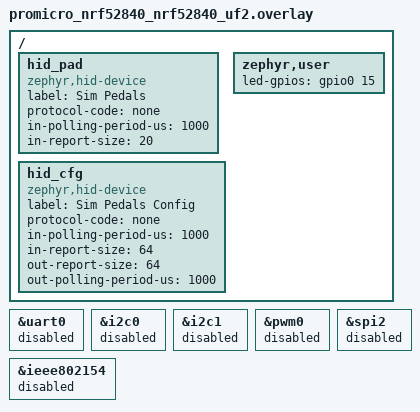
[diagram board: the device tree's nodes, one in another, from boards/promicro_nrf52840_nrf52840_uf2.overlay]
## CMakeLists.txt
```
cmake_minimum_required(VERSION 3.20.0)
find_package(Zephyr REQUIRED HINTS $ENV{ZEPHYR_BASE})
project(sim_hub)

target_include_directories(app PRIVATE ${CMAKE_CURRENT_SOURCE_DIR}/../common src)
target_sources(app PRIVATE
	src/main.c src/radio.c src/usb.c src/store.c src/usb_init.c
	../common/axis_proc.c)
```

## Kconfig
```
menu "Sim hub"

# Names kept identical to Zephyr's USB samples so usb_init.c (derived from the sample) works as is.
config SAMPLE_USBD_MANUFACTURER
	string "USB manufacturer string"
	default "DIY"

config SAMPLE_USBD_PRODUCT
	string "USB product string"
	default "Sim Pedals Hub"

config SAMPLE_USBD_PID
	hex "USB product ID"
	default 0x5E00

config SAMPLE_USBD_SELF_POWERED
	bool "Self powered attribute"

config SAMPLE_USBD_REMOTE_WAKEUP
	bool "Remote wakeup attribute"

config SAMPLE_USBD_MAX_POWER
	int "bMaxPower (2 mA units)"
	default 100

config SAMPLE_USBD_20_EXTENSION_DESC
	bool "USB 2.0 extension descriptor"

config HUB_IDLE_MINUTES
	int "Default pedal idle power-off time pushed to pedals (minutes)"
	default 20

config HUB_ACK_PAYLOAD
	bool "Send commands to pedals in ACK payloads"
	default y

config HUB_DIAG_LEVEL
	int "Bring-up ladder: 0 blinky only, 1 +USB, 2 +flash settings, 3 full hub"
	default 3

endmenu

source "Kconfig.zephyr"
```

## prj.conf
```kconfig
CONFIG_ESB=y
CONFIG_CLOCK_CONTROL=y
CONFIG_GPIO=y
CONFIG_HWINFO=y
CONFIG_REBOOT=y

# USB (new device stack), two HID interfaces: joystick + vendor config
CONFIG_USB_DEVICE_STACK_NEXT=y
CONFIG_USBD_HID_SUPPORT=y
CONFIG_USBD_CDC_ACM_CLASS=n
CONFIG_USB_DEVICE_STACK=n

# settings in flash (storage_partition, 32 kB)
CONFIG_FLASH=y
CONFIG_FLASH_MAP=y
CONFIG_FLASH_PAGE_LAYOUT=y
CONFIG_NVS=y
CONFIG_SETTINGS=y
CONFIG_SETTINGS_NVS=y

CONFIG_SERIAL=n
CONFIG_CONSOLE=n
CONFIG_UART_CONSOLE=n
CONFIG_LOG=n
CONFIG_PRINTK=n

CONFIG_ESB_MAX_PAYLOAD_LENGTH=32
CONFIG_ESB_TX_FIFO_SIZE=8
CONFIG_ESB_RX_FIFO_SIZE=8
CONFIG_ESB_PIPE_COUNT=8
CONFIG_MAIN_STACK_SIZE=4096
CONFIG_SYSTEM_WORKQUEUE_STACK_SIZE=2048
CONFIG_BUILD_OUTPUT_UF2=y

# 32 kHz source: RC is safe on clones without the 32.768 kHz crystal
CONFIG_CLOCK_CONTROL_NRF_K32SRC_RC=y
CONFIG_CLOCK_CONTROL_NRF_K32SRC_500PPM=y
```

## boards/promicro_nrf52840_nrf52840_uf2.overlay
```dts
#include <zephyr/dt-bindings/gpio/gpio.h>
/* Hub: USB gamepad (8 axes, 32 buttons) + vendor config interface */
&uart0 { status = "disabled"; };
&i2c0  { status = "disabled"; };
&i2c1  { status = "disabled"; };
&pwm0  { status = "disabled"; };
&spi2  { status = "disabled"; };
&ieee802154 { status = "disabled"; };

/ {
	hid_pad: hid_pad {
		compatible = "zephyr,hid-device";
		label = "Sim Pedals";
		protocol-code = "none";
		in-polling-period-us = <1000>;
		in-report-size = <20>;
	};

	hid_cfg: hid_cfg {
		compatible = "zephyr,hid-device";
		label = "Sim Pedals Config";
		protocol-code = "none";
		in-polling-period-us = <1000>;
		in-report-size = <64>;
		out-report-size = <64>;
		out-polling-period-us = <1000>;
	};

	zephyr,user {
		led-gpios = <&gpio0 15 GPIO_ACTIVE_HIGH>;
	};
};
```

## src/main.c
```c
#include <zephyr/kernel.h>
#include <zephyr/drivers/gpio.h>
#include <zephyr/fatal.h>
#include <zephyr/sys/reboot.h>
#include "hub.h"

/* ---- crash diagnostics (no serial available): last stage + fault reason survive a soft reset ---- */
struct dbg { uint32_t magic, stage, reason, pc; };
static __noinit struct dbg dbg;
#define DBG_MAGIC 0xD3B6C0DEu
#define STAGE(n) (dbg.stage = (n))

void k_sys_fatal_error_handler(unsigned int reason, const struct arch_esf *esf)
{
	dbg.magic = DBG_MAGIC;
	dbg.reason = reason + 1;
	dbg.pc = esf ? esf->basic.pc : 0;
	sys_reboot(SYS_REBOOT_COLD);
}

struct dev_state g_dev[N_TYPES];
bool g_dirty;
struct k_spinlock g_lock;
struct hub_stats g_stats;

static const struct gpio_dt_spec led = GPIO_DT_SPEC_GET(DT_PATH(zephyr_user), led_gpios);

/* Give every axis of a freshly seen device the next free HID axis (needs g_lock). */
void assign_slots_locked(uint8_t t)
{
	struct dev_state *d = &g_dev[t];

	for (int a = 0; a < d->n_axes && a < PP_MAX_AXES_PER_DEV; a++) {
		if (g_cfg[t][a].slot != PP_SLOT_AUTO) {
			continue;
		}
		uint8_t used = 0;

		for (int tt = 1; tt < N_TYPES; tt++) {
			for (int aa = 0; aa < PP_MAX_AXES_PER_DEV; aa++) {
				if (g_cfg[tt][aa].slot < PP_HID_AXES) {
					used |= BIT(g_cfg[tt][aa].slot);
				}
			}
		}
		for (int s = 0; s < PP_HID_AXES; s++) {
			if (!(used & BIT(s))) {
				g_cfg[t][a].slot = s;
				g_dirty = true;
				break;
			}
		}
		if (g_cfg[t][a].slot == PP_SLOT_AUTO) {
			g_cfg[t][a].slot = PP_SLOT_OFF;        /* out of HID axes */
		}
	}
}

void hub_outputs(uint16_t axes[PP_HID_AXES], int64_t now)
{
	k_spinlock_key_t k = k_spin_lock(&g_lock);

	for (int i = 0; i < PP_HID_AXES; i++) {
		axes[i] = 0;
	}
	for (int t = 1; t < N_TYPES; t++) {
		struct dev_state *d = &g_dev[t];
		bool ok = d->seen && (now - d->last_rx_ms) < LINK_TIMEOUT_MS;

		if (now - d->pps_t0 >= 1000) {          /* packets per second, also falls to 0 */
			d->pps = d->pkt_cnt;
			d->pkt_cnt = 0;
			d->pps_t0 = now;
		}

		if (!ok && d->alive) {
			d->alive = false;                   /* link lost -> re-push settings on return */
		}
		for (int a = 0; a < d->n_axes; a++) {
			uint8_t s = g_cfg[t][a].slot;

			if (s < PP_HID_AXES) {
				axes[s] = ok ? d->out[a] : 0;     /* failsafe: zero */
			}
		}
	}
	k_spin_unlock(&g_lock, k);
}

static void blinks(int n, int on_ms, int off_ms)
{
	for (int i = 0; i < n; i++) {
		gpio_pin_set_dt(&led, 1);
		k_msleep(on_ms);
		gpio_pin_set_dt(&led, 0);
		k_msleep(off_ms);
	}
}

static void blink_code(int n)
{
	/* n quick blinks, long pause, forever (USB keeps running in its own threads) */
	for (;;) {
		blinks(n, 150, 250);
		k_msleep(1500);
	}
}

/* After a crash: stage blinks (slow), pause, reason blinks (fast), 3 times, then try again. */
static void show_crash(void)
{
	int rc = dbg.reason < 6 ? (int)dbg.reason : 6 + MIN((int)dbg.reason - 17, 3);

	for (int r = 0; r < 3; r++) {
		blinks(dbg.stage, 500, 500);
		k_msleep(1500);
		blinks(rc, 120, 200);
		k_msleep(3000);
	}
	dbg.reason = 0;
}

static void diag_loop(int level)
{
	/* distinguishable patterns for the bring-up ladder */
	for (;;) {
		switch (level) {
		case 0: blinks(1, 500, 500); break;                       /* 1 Hz symmetric */
		case 1: blinks(1, 60, 1940); break;                       /* one blip per 2 s */
		default: blinks(2, 60, 200); k_msleep(1500); break;       /* double blip per 2 s */
		}
	}
}

int main(void)
{
	gpio_pin_configure_dt(&led, GPIO_OUTPUT_ACTIVE);   /* solid LED = app is running */
	if (dbg.magic != DBG_MAGIC) {
		dbg.magic = DBG_MAGIC;
		dbg.stage = 0;
		dbg.reason = 0;
	} else if (dbg.reason) {
		show_crash();
	}
	STAGE(1);
	defaults_all();
	if (CONFIG_HUB_DIAG_LEVEL == 0) {
		diag_loop(0);
	}

	/* USB first, so the PC sees the device even if flash/radio init has problems */
	STAGE(2);
	int err = usb_start();
	if (err) {
		blink_code(1);
	}
	STAGE(3);
	if (CONFIG_HUB_DIAG_LEVEL == 1) {
		diag_loop(1);
	}
	k_msleep(300);
	STAGE(4);
	store_load();                   /* settings from flash (defaults if empty) */
	if (CONFIG_HUB_DIAG_LEVEL == 2) {
		diag_loop(2);
	}

	STAGE(5);
	err = radio_start();
	if (err) {
		blink_code(2);
	}
	STAGE(6);
	for (;;) {                      /* slow heartbeat + live stream to the PC app (100 Hz) */
		for (int i = 0; i < 100; i++) {
			usb_cfg_enqueue_live();
			k_msleep(10);
		}
		gpio_pin_toggle_dt(&led);
	}
	return 0;
}
```

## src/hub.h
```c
#ifndef HUB_H
#define HUB_H
#include <zephyr/kernel.h>
#include "pedal_protocol.h"
#include "axis_proc.h"

#define FW_MAJOR 1
#define FW_MINOR 0
#define N_TYPES  (PP_DEV_MAX_TYPE + 1)   /* index = dev_type (0 unused) */
#define LINK_TIMEOUT_MS 50               /* after this the device's axes fall to 0 */

struct dev_state {
	bool     seen;
	bool     alive;
	int64_t  last_rx_ms;
	uint32_t uid;
	uint8_t  batt_20mv, flags, n_axes;
	struct pp_diag diag;
	int32_t  raw[PP_MAX_AXES_PER_DEV];
	int32_t  filt[PP_MAX_AXES_PER_DEV];
	uint16_t out[PP_MAX_AXES_PER_DEV];
	struct axis_state st[PP_MAX_AXES_PER_DEV];
	uint16_t pps, pkt_cnt;
	int64_t  pps_t0;
	uint8_t  pend_cmd, pend_p0;      /* next ACK payload */
};

extern struct dev_state g_dev[N_TYPES];
extern struct pp_axis_cfg g_cfg[N_TYPES][PP_MAX_AXES_PER_DEV];
struct hub_stats { uint32_t rx_ok, tx_ok; uint16_t rx_bad; uint8_t bad_len, bad_b0; };
extern struct hub_stats g_stats;
extern uint8_t g_idle_min;
extern bool g_dirty;                 /* config changed by auto slot assignment */
extern struct k_spinlock g_lock;

void defaults_all(void);
int  store_load(void);
int  store_save(void);

int  radio_start(void);

void assign_slots_locked(uint8_t t);          /* needs g_lock */
void hub_outputs(uint16_t axes[PP_HID_AXES], int64_t now);

int  usb_start(void);
void usb_cfg_enqueue_live(void);
#endif
```

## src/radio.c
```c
#include "hub.h"
#if IS_ENABLED(CONFIG_ESB)
#include <zephyr/drivers/clock_control/nrf_clock_control.h>
#include <esb.h>
#include <string.h>

static uint8_t ack_queued[N_TYPES];
static uint16_t rx_since_ack[N_TYPES];

static void queue_ack(uint8_t t)
{
	struct esb_payload ack = {.pipe = t, .length = sizeof(struct pp_ack)};
	struct pp_ack *a = (struct pp_ack *)ack.data;
	struct dev_state *d = &g_dev[t];

	a->type = PP_PKT_ACK;
	a->cmd = d->pend_cmd;
	a->p0 = d->pend_p0;
	a->p1 = 0;
	if (esb_write_payload(&ack) == 0) {
		ack_queued[t] = 1;
		rx_since_ack[t] = 0;
		d->pend_cmd = PP_CMD_NONE;
	}
}

static void on_data(const struct esb_payload *p)
{
	const struct pp_data *m = (const struct pp_data *)p->data;
	uint8_t t = p->pipe;

	/* p->data has a fixed buffer size; only p->length bytes are valid. */
	if (p->length < PP_DATA_HDR_LEN) {
		g_stats.rx_bad++;
		g_stats.bad_len = p->length;
		g_stats.bad_b0 = p->length ? p->data[0] : 0;
		return;
	}
	if (m->type != PP_PKT_DATA || t < 1 || t > PP_DEV_MAX_TYPE ||
	    m->dev_type != t || m->n_axes == 0 || m->n_axes > PP_MAX_AXES_PER_DEV) {
		g_stats.rx_bad++;
		g_stats.bad_len = p->length;
		g_stats.bad_b0 = p->data[0];
		return;
	}
	bool has_diag = (m->flags & PP_FLAG_DIAG_EXT) != 0;
	size_t expected_len = has_diag ? PP_DATA_DIAG_LEN(m->n_axes) : PP_DATA_LEN(m->n_axes);
	if (p->length != expected_len ||
	    (has_diag && (t != PP_DEV_PEDALS || m->n_axes != 3)) ||
	    (has_diag && !(m->flags & PP_FLAG_SENSOR_ERR))) {
		g_stats.rx_bad++;
		g_stats.bad_len = p->length;
		g_stats.bad_b0 = p->data[0];
		return;
	}
	int64_t now = k_uptime_get();
	k_spinlock_key_t k = k_spin_lock(&g_lock);
	struct dev_state *d = &g_dev[t];

	if (!d->alive) {                      /* device (re)appeared: push idle timeout to it */
		d->pend_cmd = PP_CMD_SET_IDLE;
		d->pend_p0 = g_idle_min;
	}
	d->alive = true;
	d->seen = true;
	d->last_rx_ms = now;
	d->uid = m->uid;
	d->flags = m->flags;
	d->batt_20mv = m->batt_20mv;
	d->n_axes = m->n_axes;
	if (has_diag) {
		memcpy(&d->diag, &m->axes[m->n_axes * 3], sizeof(d->diag));
	} else {
		memset(&d->diag, 0, sizeof(d->diag));
	}
	for (int i = 0; i < m->n_axes; i++) {
		int32_t raw = pp_get_i24(&m->axes[i * 3]);

		d->raw[i] = raw;
		d->out[i] = axis_process(&g_cfg[t][i], &d->st[i], raw, &d->filt[i]);
	}
	assign_slots_locked(t);
	d->pkt_cnt++;
	g_stats.rx_ok++;
	k_spin_unlock(&g_lock, k);

	if (ack_queued[t] && ++rx_since_ack[t] > 100) {   /* ACK never got out: reset FIFO */
		esb_flush_tx();
		memset(ack_queued, 0, sizeof(ack_queued));
	}
	if (IS_ENABLED(CONFIG_HUB_ACK_PAYLOAD) && !ack_queued[t]) {
		queue_ack(t);
	}
}

static void esb_handler(struct esb_evt const *ev)
{
	static struct esb_payload rx;

	switch (ev->evt_id) {
	case ESB_EVENT_TX_SUCCESS:             /* an ACK payload went out */
		g_stats.tx_ok++;
		for (int t = 1; t < N_TYPES; t++) {
			ack_queued[t] = 0;
		}
		break;
	case ESB_EVENT_RX_RECEIVED:
		while (esb_read_rx_payload(&rx) == 0) {
			on_data(&rx);
		}
		break;
	default:
		break;
	}
}

static int clocks_start(void)
{
	struct onoff_manager *mgr = z_nrf_clock_control_get_onoff(CLOCK_CONTROL_NRF_SUBSYS_HF);
	struct onoff_client cli;
	int res, err;

	if (!mgr) {
		return -ENXIO;
	}
	sys_notify_init_spinwait(&cli.notify);
	err = onoff_request(mgr, &cli);
	if (err < 0) {
		return err;
	}
	do {
		err = sys_notify_fetch_result(&cli.notify, &res);
	} while (err == -EAGAIN);
	return err ? err : res;
}

int radio_start(void)
{
	uint8_t b0[4] = PP_BASE_ADDR_0, b1[4] = PP_BASE_ADDR_1, pf[8] = PP_PREFIXES;
	struct esb_config c = ESB_DEFAULT_CONFIG;
	int err;

	if ((err = clocks_start())) {
		return err;
	}
	c.protocol = ESB_PROTOCOL_ESB_DPL;
	c.mode = ESB_MODE_PRX;
	c.event_handler = esb_handler;
	c.bitrate = ESB_BITRATE_2MBPS;
	c.crc = ESB_CRC_16BIT;
	c.selective_auto_ack = false;

	if ((err = esb_init(&c)) || (err = esb_set_base_address_0(b0)) ||
	    (err = esb_set_base_address_1(b1)) || (err = esb_set_prefixes(pf, 8)) ||
	    (err = esb_set_rf_channel(PP_RF_CHANNEL))) {
		return err;
	}
	return esb_start_rx();
}

#else
int radio_start(void) { return 0; }
#endif
```

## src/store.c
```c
#include <string.h>
#include <zephyr/settings/settings.h>
#include "hub.h"

#define STORE_MAGIC 0x50454431u   /* "PED1" */

struct blob {
	uint32_t magic;
	struct pp_axis_cfg cfg[PP_MAX_AXES_PER_DEV];
};

struct pp_axis_cfg g_cfg[N_TYPES][PP_MAX_AXES_PER_DEV];
uint8_t g_idle_min = CONFIG_HUB_IDLE_MINUTES;

void defaults_all(void)
{
	for (int t = 0; t < N_TYPES; t++) {
		for (int a = 0; a < PP_MAX_AXES_PER_DEV; a++) {
			axis_defaults(&g_cfg[t][a], 0, 1000000);
		}
	}
	/* pedals: Hall axes are 14-bit (centered around ~7500 at 3.3 V), brake is ADS1220 24-bit */
	axis_defaults(&g_cfg[PP_DEV_PEDALS][PP_PEDAL_CLUTCH], 4000, 12000);
	axis_defaults(&g_cfg[PP_DEV_PEDALS][PP_PEDAL_THROTTLE], 4000, 12000);
	axis_defaults(&g_cfg[PP_DEV_PEDALS][PP_PEDAL_BRAKE], 0, 1000000);
	g_cfg[PP_DEV_PEDALS][PP_PEDAL_BRAKE].full_scale_dkg = 1000;   /* 100 kg, set by calibration */
	for (int a = 3; a < PP_MAX_AXES_PER_DEV; a++) {
		g_cfg[PP_DEV_PEDALS][a].slot = PP_SLOT_OFF;
	}
	g_idle_min = CONFIG_HUB_IDLE_MINUTES;
}

static int set_cb(const char *name, size_t len, settings_read_cb read_cb, void *cb_arg)
{
	if (name[0] == 'd' && name[1] >= '1' && name[1] <= '7' && name[2] == 0) {
		struct blob b;
		int t = name[1] - '0';

		if (len == sizeof(b) && read_cb(cb_arg, &b, sizeof(b)) == sizeof(b) &&
		    b.magic == STORE_MAGIC) {
			for (int a = 0; a < PP_MAX_AXES_PER_DEV; a++) {
				axis_cfg_validate(&b.cfg[a]);
			}
			memcpy(g_cfg[t], b.cfg, sizeof(b.cfg));
		}
		return 0;
	}
	if (!strcmp(name, "idle")) {
		uint8_t v;

		if (read_cb(cb_arg, &v, 1) == 1) {
			g_idle_min = v;
		}
	}
	return 0;
}

SETTINGS_STATIC_HANDLER_DEFINE(hub, "hub", NULL, set_cb, NULL, NULL);

int store_load(void)
{
	defaults_all();
	int err = settings_subsys_init();

	if (err) {
		return err;
	}
	return settings_load_subtree("hub");
}

int store_save(void)
{
	struct blob b;
	char key[] = "hub/dX";
	int err = 0;

	for (int t = 1; t <= PP_DEV_MAX_TYPE; t++) {
		k_spinlock_key_t k = k_spin_lock(&g_lock);

		b.magic = STORE_MAGIC;
		memcpy(b.cfg, g_cfg[t], sizeof(b.cfg));
		k_spin_unlock(&g_lock, k);
		key[5] = (char)('0' + t);
		err |= settings_save_one(key, &b, sizeof(b));
	}
	err |= settings_save_one("hub/idle", &g_idle_min, 1);
	g_dirty = false;
	return err;
}
```

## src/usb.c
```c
/*
 * USB side of the hub:
 *   interface 0: HID joystick, 8 x 16-bit axes + 32 buttons (static descriptor, 20-byte report)
 *   interface 1: vendor HID (usage page 0xFF00), 64-byte in/out reports, config + live data
 */
#include <string.h>
#include <zephyr/device.h>
#include <zephyr/usb/usbd.h>
#include <zephyr/usb/class/usbd_hid.h>
#include <zephyr/sys/reboot.h>
#include <zephyr/drivers/hwinfo.h>
#include <nrf.h>
#include "hub.h"
#include "usb_init.h"

/* ------------------------------------------------------------- descriptors */
static const uint8_t pad_desc[] = {
	0x05, 0x01,             /* Usage Page (Generic Desktop) */
	0x09, 0x04,             /* Usage (Joystick) */
	0xA1, 0x01,             /* Collection (Application) */
	0x09, 0x30, 0x09, 0x31, 0x09, 0x32, 0x09, 0x33,   /* X Y Z Rx */
	0x09, 0x34, 0x09, 0x35, 0x09, 0x36, 0x09, 0x37,   /* Ry Rz Slider Dial */
	0x15, 0x00,             /* Logical Min 0 */
	0x27, 0xFF, 0xFF, 0x00, 0x00,   /* Logical Max 65535 */
	0x75, 0x10,             /* Report Size 16 */
	0x95, 0x08,             /* Report Count 8 */
	0x81, 0x02,             /* Input (Data,Var,Abs) */
	0x05, 0x09,             /* Usage Page (Button) */
	0x19, 0x01, 0x29, 0x20, /* Buttons 1..32 */
	0x15, 0x00, 0x25, 0x01,
	0x75, 0x01, 0x95, 0x20,
	0x81, 0x02,
	0xC0,
};
#define PAD_REPORT_LEN 20

static const uint8_t cfg_desc[] = {
	0x06, 0x00, 0xFF,       /* Usage Page (Vendor 0xFF00) */
	0x09, 0x01,             /* Usage (1) */
	0xA1, 0x01,             /* Collection (Application) */
	0x09, 0x02, 0x15, 0x00, 0x26, 0xFF, 0x00, 0x75, 0x08, 0x95, 0x40, 0x81, 0x02,  /* Input 64 */
	0x09, 0x03, 0x15, 0x00, 0x26, 0xFF, 0x00, 0x75, 0x08, 0x95, 0x40, 0x91, 0x02,  /* Output 64 */
	0xC0,
};

static const struct device *pad_dev = DEVICE_DT_GET(DT_NODELABEL(hid_pad));
static const struct device *cfg_dev = DEVICE_DT_GET(DT_NODELABEL(hid_cfg));

/* ------------------------------------------------------------- joystick */
static uint8_t pad_report[PAD_REPORT_LEN] __aligned(4);
static K_SEM_DEFINE(pad_done, 0, 1);
static volatile bool pad_ready;
static uint32_t g_buttons;

static void pad_iface_ready(const struct device *d, const bool ready)
{
	pad_ready = ready;
	if (ready) {
		k_sem_give(&pad_done);
	}
}
static void pad_in_done(const struct device *d, const uint8_t *r)
{
	k_sem_give(&pad_done);
}
static int pad_get_report(const struct device *d, const uint8_t t, const uint8_t id,
			  const uint16_t len, uint8_t *const buf)
{
	if (t != 1 /* input */ || len < PAD_REPORT_LEN) {
		return -ENOTSUP;
	}
	memcpy(buf, pad_report, PAD_REPORT_LEN);
	return PAD_REPORT_LEN;
}
static const struct hid_device_ops pad_ops = {
	.iface_ready = pad_iface_ready,
	.get_report = pad_get_report,
	.input_report_done = pad_in_done,
};

static void pad_thread(void *a, void *b, void *c)
{
	for (;;) {
		k_sem_take(&pad_done, K_MSEC(20));
		if (!pad_ready) {
			continue;
		}
		uint16_t ax[PP_HID_AXES];

		hub_outputs(ax, k_uptime_get());
		for (int i = 0; i < PP_HID_AXES; i++) {
			pad_report[2 * i] = ax[i] & 0xFF;
			pad_report[2 * i + 1] = ax[i] >> 8;
		}
		memcpy(&pad_report[16], &g_buttons, 4);
		if (hid_device_submit_report(pad_dev, PAD_REPORT_LEN, pad_report)) {
			k_msleep(1);
			k_sem_give(&pad_done);   /* retry */
		}
	}
}
K_THREAD_DEFINE(pad_tid, 2048, pad_thread, NULL, NULL, NULL, 5, 0, 0);

/* ------------------------------------------------------------- config channel */
struct frame { uint8_t d[PP_CFG_REPORT_LEN]; };
K_MSGQ_DEFINE(rx_q, sizeof(struct frame), 8, 4);
K_MSGQ_DEFINE(tx_q, sizeof(struct frame), 8, 4);
static K_SEM_DEFINE(cfg_tx_done, 1, 1);
static volatile bool cfg_ready, stream_on;
static uint8_t live_ctr;

static void cfg_iface_ready(const struct device *d, const bool ready)
{
	cfg_ready = ready;
	if (!ready) {
		stream_on = false;
	}
}
static void cfg_in_done(const struct device *d, const uint8_t *r)
{
	k_sem_give(&cfg_tx_done);
}
static void cfg_out(const struct device *d, const uint16_t len, const uint8_t *const buf)
{
	struct frame f = {0};

	memcpy(f.d, buf, MIN(len, PP_CFG_REPORT_LEN));
	k_msgq_put(&rx_q, &f, K_NO_WAIT);
}
static int cfg_set_report(const struct device *d, const uint8_t t, const uint8_t id,
			  const uint16_t len, const uint8_t *const buf)
{
	if (t == 2 /* output */) {
		cfg_out(d, len, buf);
		return 0;
	}
	return -ENOTSUP;
}
static int cfg_get_report(const struct device *d, const uint8_t t, const uint8_t id,
			  const uint16_t len, uint8_t *const buf)
{
	return -ENOTSUP;
}
static const struct hid_device_ops cfg_ops = {
	.iface_ready = cfg_iface_ready,
	.get_report = cfg_get_report,
	.set_report = cfg_set_report,
	.input_report_done = cfg_in_done,
	.output_report = cfg_out,
};

static void tx_thread(void *a, void *b, void *c)
{
	static struct frame f __aligned(4);

	for (;;) {
		k_msgq_get(&tx_q, &f, K_FOREVER);
		if (!cfg_ready) {
			continue;
		}
		if (k_sem_take(&cfg_tx_done, K_MSEC(100)) != 0) {
			k_sem_give(&cfg_tx_done);      /* host not reading: drop, don't wedge */
			continue;
		}
		if (hid_device_submit_report(cfg_dev, PP_CFG_REPORT_LEN, f.d)) {
			k_sem_give(&cfg_tx_done);
		}
	}
}
K_THREAD_DEFINE(tx_tid, 2048, tx_thread, NULL, NULL, NULL, 6, 0, 0);

static void reply(const uint8_t *req, uint8_t status, const void *data, size_t n)
{
	struct frame f = {0};

	f.d[0] = req[0];
	f.d[1] = req[1];
	f.d[2] = status;
	if (data && n) {
		memcpy(&f.d[3], data, MIN(n, PP_CFG_REPORT_LEN - 3));
	}
	k_msgq_put(&tx_q, &f, K_MSEC(20));
}

static void handle(const uint8_t *r)
{
	uint8_t cmd = r[0];
	uint8_t t = r[2], a = r[3];

	switch (cmd) {
	case PP_CMD_GET_INFO: {
		uint8_t info[16] = {PP_VERSION, FW_MAJOR, FW_MINOR, PP_HID_AXES, 0, g_idle_min};
		uint32_t id = NRF_FICR->DEVICEID[0];

		for (int i = 1; i < N_TYPES; i++) {
			if (g_dev[i].seen) {
				info[4] |= BIT(i);
			}
		}
		memcpy(&info[6], &id, 4);
		reply(r, PP_ST_OK, info, sizeof(info));
		break;
	}
	case PP_CMD_GET_AXIS: {
		if (t < 1 || t > PP_DEV_MAX_TYPE || a >= PP_MAX_AXES_PER_DEV) {
			reply(r, PP_ST_BADARG, NULL, 0);
			break;
		}
		struct pp_axis_cfg c;
		k_spinlock_key_t k = k_spin_lock(&g_lock);
		c = g_cfg[t][a];
		k_spin_unlock(&g_lock, k);
		reply(r, PP_ST_OK, &c, sizeof(c));
		break;
	}
	case PP_CMD_SET_AXIS: {
		struct pp_axis_cfg c;

		if (t < 1 || t > PP_DEV_MAX_TYPE || a >= PP_MAX_AXES_PER_DEV) {
			reply(r, PP_ST_BADARG, NULL, 0);
			break;
		}
		memcpy(&c, &r[4], sizeof(c));
		axis_cfg_validate(&c);
		k_spinlock_key_t k = k_spin_lock(&g_lock);
		g_cfg[t][a] = c;
		g_dev[t].st[a].primed = 0;
		assign_slots_locked(t);
		k_spin_unlock(&g_lock, k);
		reply(r, PP_ST_OK, NULL, 0);
		break;
	}
	case PP_CMD_SAVE:
		reply(r, store_save() ? PP_ST_UNKNOWN : PP_ST_OK, NULL, 0);
		break;
	case PP_CMD_DEFAULTS: {
		k_spinlock_key_t k = k_spin_lock(&g_lock);
		defaults_all();
		k_spin_unlock(&g_lock, k);
		reply(r, PP_ST_OK, NULL, 0);
		break;
	}
	case PP_CMD_TARE: {
		if (t < 1 || t > PP_DEV_MAX_TYPE || a >= PP_MAX_AXES_PER_DEV || !g_dev[t].alive) {
			reply(r, PP_ST_NODEV, NULL, 0);
			break;
		}
		k_spinlock_key_t k = k_spin_lock(&g_lock);
		g_cfg[t][a].cal_min = g_dev[t].filt[a];
		k_spin_unlock(&g_lock, k);
		reply(r, PP_ST_OK, NULL, 0);
		break;
	}
	case PP_CMD_STREAM:
		stream_on = r[2] != 0;
		reply(r, PP_ST_OK, NULL, 0);
		break;
	case PP_CMD_DEV_CMD: {         /* payload: dev_type, ack_cmd, p0 */
		if (t < 1 || t > PP_DEV_MAX_TYPE) {
			reply(r, PP_ST_BADARG, NULL, 0);
			break;
		}
		k_spinlock_key_t k = k_spin_lock(&g_lock);
		g_dev[t].pend_cmd = r[3];
		g_dev[t].pend_p0 = r[4];
		if (r[3] == PP_CMD_SET_IDLE) {
			g_idle_min = r[4];
		}
		k_spin_unlock(&g_lock, k);
		reply(r, PP_ST_OK, NULL, 0);
		break;
	}
	case PP_CMD_BOOTLOADER:
		reply(r, PP_ST_OK, NULL, 0);
		k_msleep(100);
		NRF_POWER->GPREGRET = 0x57;          /* Adafruit UF2 bootloader magic */
		sys_reboot(SYS_REBOOT_COLD);
		break;
	default:
		reply(r, PP_ST_UNKNOWN, NULL, 0);
		break;
	}
}

static void rx_thread(void *a, void *b, void *c)
{
	struct frame f;
	int64_t last_save = 0;

	for (;;) {
		if (k_msgq_get(&rx_q, &f, K_MSEC(500)) == 0) {
			handle(f.d);
		}
		/* slots were auto-assigned by a new device: persist after things settle */
		if (g_dirty && k_uptime_get() - last_save > 3000) {
			last_save = k_uptime_get();
			store_save();
		}
	}
}
K_THREAD_DEFINE(rx_tid, 4096, rx_thread, NULL, NULL, NULL, 7, 0, 0);

/* live frame: [0]=PP_CMD_LIVE [1]=ctr [2]=ndev, per device:
 *   type u8, batt_20mv u8, flags u8, alive u8, pps u16, n u8, n x { raw i32, out u16 } */
void usb_cfg_enqueue_live(void)
{
	if (!stream_on || !cfg_ready || k_msgq_num_used_get(&tx_q) > 0) {
		return;
	}
	struct frame f = {0};
	int pos = 3, nd = 0;
	int64_t now = k_uptime_get();
	k_spinlock_key_t k = k_spin_lock(&g_lock);

	for (int t = 1; t < N_TYPES; t++) {
		struct dev_state *d = &g_dev[t];

		if (!d->seen) {
			continue;
		}
		int n = d->n_axes;
		bool has_diag = (d->flags & PP_FLAG_DIAG_EXT) != 0;
		int extra = has_diag ? PP_DIAG_LEN : 0;

		if (pos + 7 + 6 * n + extra > 52) {
			break;
		}
		f.d[pos++] = t;
		f.d[pos++] = d->batt_20mv;
		f.d[pos++] = d->flags;
		f.d[pos++] = (now - d->last_rx_ms) < LINK_TIMEOUT_MS;
		f.d[pos++] = d->pps & 0xFF;
		f.d[pos++] = d->pps >> 8;
		f.d[pos++] = n;
		for (int i = 0; i < n; i++) {
			memcpy(&f.d[pos], &d->raw[i], 4);
			pos += 4;
			f.d[pos++] = d->out[i] & 0xFF;
			f.d[pos++] = d->out[i] >> 8;
		}
		if (has_diag) {
			memcpy(&f.d[pos], &d->diag, PP_DIAG_LEN);
			pos += PP_DIAG_LEN;
		}
		nd++;
	}
	memcpy(&f.d[52], &g_stats.rx_ok, 4);
	memcpy(&f.d[56], &g_stats.tx_ok, 4);
	memcpy(&f.d[60], &g_stats.rx_bad, 2);
	f.d[62] = g_stats.bad_len;
	f.d[63] = g_stats.bad_b0;
	k_spin_unlock(&g_lock, k);
	f.d[0] = PP_CMD_LIVE;
	f.d[1] = live_ctr++;
	f.d[2] = nd;
	k_msgq_put(&tx_q, &f, K_NO_WAIT);
}

int usb_start(void)
{
	struct usbd_context *ctx;
	int err;

	if (!device_is_ready(pad_dev) || !device_is_ready(cfg_dev)) {
		return -ENODEV;
	}
	err = hid_device_register(pad_dev, pad_desc, sizeof(pad_desc), &pad_ops);
	if (err) {
		return err;
	}
	err = hid_device_register(cfg_dev, cfg_desc, sizeof(cfg_desc), &cfg_ops);
	if (err) {
		return err;
	}
	ctx = sample_usbd_init_device(NULL);
	if (!ctx) {
		return -ENODEV;
	}
	return usbd_enable(ctx);
}
```

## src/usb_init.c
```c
/*
 * Copyright (c) 2023 Nordic Semiconductor ASA
 *
 * SPDX-License-Identifier: Apache-2.0
 */

#include <stdint.h>

#include <zephyr/device.h>
#include <zephyr/usb/usbd.h>
#include <zephyr/usb/bos.h>

#include <zephyr/logging/log.h>
LOG_MODULE_REGISTER(usbd_sample_config);

#include "pedal_protocol.h"
#define ZEPHYR_PROJECT_USB_VID		PP_USB_VID

/* By default, do not register the USB DFU class DFU mode instance. */
static const char *const blocklist[] = {
	"dfu_dfu",
	NULL,
};

/* doc device instantiation start */
/*
 * Instantiate a context named sample_usbd using the default USB device
 * controller, the Zephyr project vendor ID, and the sample product ID.
 * Zephyr project vendor ID must not be used outside of Zephyr samples.
 */
USBD_DEVICE_DEFINE(sample_usbd,
		   DEVICE_DT_GET(DT_NODELABEL(zephyr_udc0)),
		   ZEPHYR_PROJECT_USB_VID, CONFIG_SAMPLE_USBD_PID);
/* doc device instantiation end */

/* doc string instantiation start */
USBD_DESC_LANG_DEFINE(sample_lang);
USBD_DESC_MANUFACTURER_DEFINE(sample_mfr, CONFIG_SAMPLE_USBD_MANUFACTURER);
USBD_DESC_PRODUCT_DEFINE(sample_product, CONFIG_SAMPLE_USBD_PRODUCT);
IF_ENABLED(CONFIG_HWINFO, (USBD_DESC_SERIAL_NUMBER_DEFINE(sample_sn)));

/* doc string instantiation end */

USBD_DESC_CONFIG_DEFINE(fs_cfg_desc, "FS Configuration");
USBD_DESC_CONFIG_DEFINE(hs_cfg_desc, "HS Configuration");

/* doc configuration instantiation start */
static const uint8_t attributes = (IS_ENABLED(CONFIG_SAMPLE_USBD_SELF_POWERED) ?
				   USB_SCD_SELF_POWERED : 0) |
				  (IS_ENABLED(CONFIG_SAMPLE_USBD_REMOTE_WAKEUP) ?
				   USB_SCD_REMOTE_WAKEUP : 0);

/* Full speed configuration */
USBD_CONFIGURATION_DEFINE(sample_fs_config,
			  attributes,
			  CONFIG_SAMPLE_USBD_MAX_POWER, &fs_cfg_desc);

/* High speed configuration */
USBD_CONFIGURATION_DEFINE(sample_hs_config,
			  attributes,
			  CONFIG_SAMPLE_USBD_MAX_POWER, &hs_cfg_desc);
/* doc configuration instantiation end */

#if CONFIG_SAMPLE_USBD_20_EXTENSION_DESC
/*
 * This does not yet provide valuable information, but rather serves as an
 * example, and will be improved in the future.
 */
static const struct usb_bos_capability_lpm bos_cap_lpm = {
	.bLength = sizeof(struct usb_bos_capability_lpm),
	.bDescriptorType = USB_DESC_DEVICE_CAPABILITY,
	.bDevCapabilityType = USB_BOS_CAPABILITY_EXTENSION,
	.bmAttributes = 0UL,
};

USBD_DESC_BOS_DEFINE(sample_usbext, sizeof(bos_cap_lpm), &bos_cap_lpm);
#endif

static void sample_fix_code_triple(struct usbd_context *uds_ctx,
				   const enum usbd_speed speed)
{
	/* Always use class code information from Interface Descriptors */
	if (IS_ENABLED(CONFIG_USBD_CDC_ACM_CLASS) ||
	    IS_ENABLED(CONFIG_USBD_CDC_ECM_CLASS) ||
	    IS_ENABLED(CONFIG_USBD_CDC_NCM_CLASS) ||
	    IS_ENABLED(CONFIG_USBD_MIDI2_CLASS) ||
	    IS_ENABLED(CONFIG_USBD_AUDIO2_CLASS)) {
		/*
		 * Class with multiple interfaces have an Interface
		 * Association Descriptor available, use an appropriate triple
		 * to indicate it.
		 */
		usbd_device_set_code_triple(uds_ctx, speed,
					    USB_BCC_MISCELLANEOUS, 0x02, 0x01);
	} else {
		usbd_device_set_code_triple(uds_ctx, speed, 0, 0, 0);
	}
}

struct usbd_context *sample_usbd_setup_device(usbd_msg_cb_t msg_cb)
{
	int err;

	/* doc add string descriptor start */
	err = usbd_add_descriptor(&sample_usbd, &sample_lang);
	if (err) {
		LOG_ERR("Failed to initialize language descriptor (%d)", err);
		return NULL;
	}

	err = usbd_add_descriptor(&sample_usbd, &sample_mfr);
	if (err) {
		LOG_ERR("Failed to initialize manufacturer descriptor (%d)", err);
		return NULL;
	}

	err = usbd_add_descriptor(&sample_usbd, &sample_product);
	if (err) {
		LOG_ERR("Failed to initialize product descriptor (%d)", err);
		return NULL;
	}

	IF_ENABLED(CONFIG_HWINFO, (
		err = usbd_add_descriptor(&sample_usbd, &sample_sn);
	))
	if (err) {
		LOG_ERR("Failed to initialize SN descriptor (%d)", err);
		return NULL;
	}
	/* doc add string descriptor end */

	if (USBD_SUPPORTS_HIGH_SPEED &&
	    usbd_caps_speed(&sample_usbd) == USBD_SPEED_HS) {
		err = usbd_add_configuration(&sample_usbd, USBD_SPEED_HS,
					     &sample_hs_config);
		if (err) {
			LOG_ERR("Failed to add High-Speed configuration");
			return NULL;
		}

		err = usbd_register_all_classes(&sample_usbd, USBD_SPEED_HS, 1,
						blocklist);
		if (err) {
			LOG_ERR("Failed to add register classes");
			return NULL;
		}

		sample_fix_code_triple(&sample_usbd, USBD_SPEED_HS);
	}

	/* doc configuration register start */
	err = usbd_add_configuration(&sample_usbd, USBD_SPEED_FS,
				     &sample_fs_config);
	if (err) {
		LOG_ERR("Failed to add Full-Speed configuration");
		return NULL;
	}
	/* doc configuration register end */

	/* doc functions register start */
	err = usbd_register_all_classes(&sample_usbd, USBD_SPEED_FS, 1, blocklist);
	if (err) {
		LOG_ERR("Failed to add register classes");
		return NULL;
	}
	/* doc functions register end */

	sample_fix_code_triple(&sample_usbd, USBD_SPEED_FS);
	usbd_self_powered(&sample_usbd, attributes & USB_SCD_SELF_POWERED);

	if (msg_cb != NULL) {
		/* doc device init-and-msg start */
		err = usbd_msg_register_cb(&sample_usbd, msg_cb);
		if (err) {
			LOG_ERR("Failed to register message callback");
			return NULL;
		}
		/* doc device init-and-msg end */
	}

#if CONFIG_SAMPLE_USBD_20_EXTENSION_DESC
	(void)usbd_device_set_bcd_usb(&sample_usbd, USBD_SPEED_FS, 0x0201);
	(void)usbd_device_set_bcd_usb(&sample_usbd, USBD_SPEED_HS, 0x0201);

	err = usbd_add_descriptor(&sample_usbd, &sample_usbext);
	if (err) {
		LOG_ERR("Failed to add USB 2.0 Extension Descriptor");
		return NULL;
	}
#endif

	return &sample_usbd;
}

struct usbd_context *sample_usbd_init_device(usbd_msg_cb_t msg_cb)
{
	int err;

	if (sample_usbd_setup_device(msg_cb) == NULL) {
		return NULL;
	}

	/* doc device init start */
	err = usbd_init(&sample_usbd);
	if (err) {
		LOG_ERR("Failed to initialize device support");
		return NULL;
	}
	/* doc device init end */

	return &sample_usbd;
}
```
